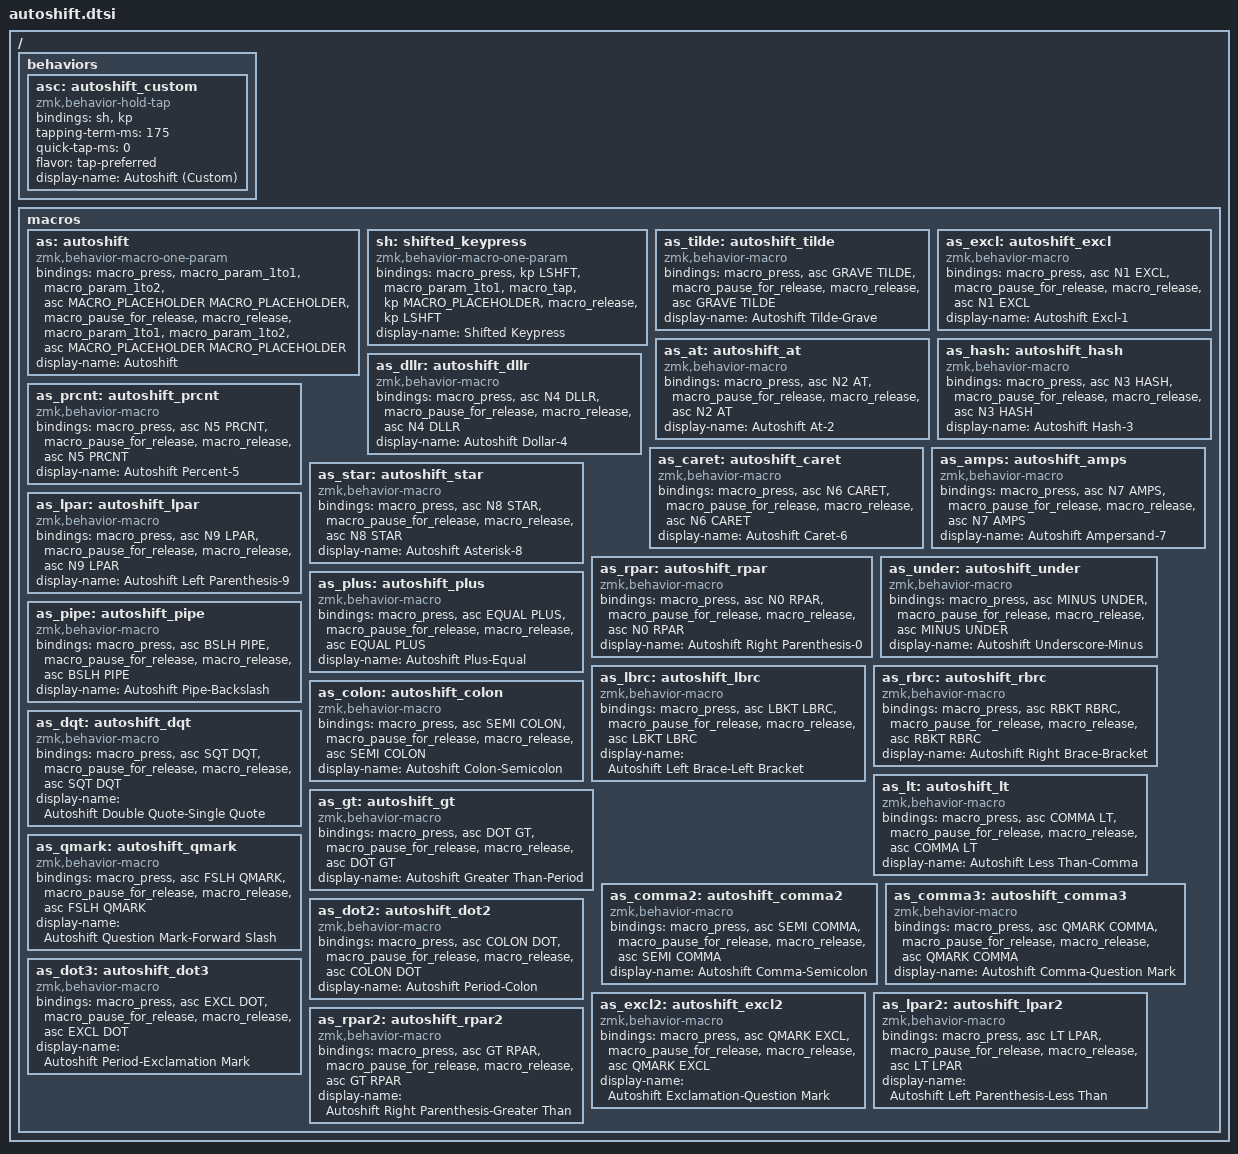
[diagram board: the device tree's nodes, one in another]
#include <dt-bindings/zmk/keys.h>

/ {
    behaviors {
        asc: autoshift_custom {
            compatible = "zmk,behavior-hold-tap";
            #binding-cells = <2>;
            bindings = <&sh>, <&kp>;
            tapping-term-ms = <175>;
            quick-tap-ms = <0>;
            flavor = "tap-preferred";
            display-name = "Autoshift (Custom)";
        };
    };

    macros {
        as: autoshift {
            compatible = "zmk,behavior-macro-one-param";
            #binding-cells = <1>;
            bindings
                = <&macro_press>
                , <&macro_param_1to1>
                , <&macro_param_1to2>
                , <&asc MACRO_PLACEHOLDER MACRO_PLACEHOLDER>
                , <&macro_pause_for_release>
                , <&macro_release>
                , <&macro_param_1to1>
                , <&macro_param_1to2>
                , <&asc MACRO_PLACEHOLDER MACRO_PLACEHOLDER>
                ;
            display-name = "Autoshift";
        };

        sh: shifted_keypress {
            compatible = "zmk,behavior-macro-one-param";
            #binding-cells = <1>;
            bindings
                = <&macro_press &kp LSHFT>
                , <&macro_param_1to1>
                , <&macro_tap &kp MACRO_PLACEHOLDER>
                , <&macro_release &kp LSHFT>
                ;
            display-name = "Shifted Keypress";
        };


        #define AS_TILDE  &asc GRAVE TILDE
        as_tilde:  autoshift_tilde {
            compatible = "zmk,behavior-macro";
            #binding-cells = <0>;
            bindings
                = <&macro_press>
                , <&asc GRAVE TILDE>
                , <&macro_pause_for_release>
                , <&macro_release>
                , <&asc GRAVE TILDE>
                ;
            display-name = "Autoshift Tilde-Grave";
        };

        as_excl: autoshift_excl {
            compatible = "zmk,behavior-macro";
            #binding-cells = <0>;
            bindings
                = <&macro_press>
                , <&asc N1 EXCL>
                , <&macro_pause_for_release>
                , <&macro_release>
                , <&asc N1 EXCL>
                ;
            display-name = "Autoshift Excl-1";
        };

        as_at: autoshift_at {
            compatible = "zmk,behavior-macro";
            #binding-cells = <0>;
            bindings
                = <&macro_press>
                , <&asc N2 AT>
                , <&macro_pause_for_release>
                , <&macro_release>
                , <&asc N2 AT>
                ;
            display-name = "Autoshift At-2";
        };

        as_hash: autoshift_hash {
            compatible = "zmk,behavior-macro";
            #binding-cells = <0>;
            bindings
                = <&macro_press>
                , <&asc N3 HASH>
                , <&macro_pause_for_release>
                , <&macro_release>
                , <&asc N3 HASH>
                ;
            display-name = "Autoshift Hash-3";
        };

        as_dllr: autoshift_dllr {
            compatible = "zmk,behavior-macro";
            #binding-cells = <0>;
            bindings
                = <&macro_press>
                , <&asc N4 DLLR>
                , <&macro_pause_for_release>
                , <&macro_release>
                , <&asc N4 DLLR>
                ;
            display-name = "Autoshift Dollar-4";
        };

        as_prcnt: autoshift_prcnt {
            compatible = "zmk,behavior-macro";
            #binding-cells = <0>;
            bindings
                = <&macro_press>
                , <&asc N5 PRCNT>
                , <&macro_pause_for_release>
                , <&macro_release>
                , <&asc N5 PRCNT>
                ;
            display-name = "Autoshift Percent-5";
        };

        as_caret: autoshift_caret {
            compatible = "zmk,behavior-macro";
            #binding-cells = <0>;
            bindings
                = <&macro_press>
                , <&asc N6 CARET>
                , <&macro_pause_for_release>
                , <&macro_release>
                , <&asc N6 CARET>
                ;
            display-name = "Autoshift Caret-6";
        };

        as_amps: autoshift_amps {
            compatible = "zmk,behavior-macro";
            #binding-cells = <0>;
            bindings
                = <&macro_press>
                , <&asc N7 AMPS>
                , <&macro_pause_for_release>
                , <&macro_release>
                , <&asc N7 AMPS>
                ;
            display-name = "Autoshift Ampersand-7";
        };

        as_star: autoshift_star {
            compatible = "zmk,behavior-macro";
            #binding-cells = <0>;
            bindings
                = <&macro_press>
                , <&asc N8 STAR>
                , <&macro_pause_for_release>
                , <&macro_release>
                , <&asc N8 STAR>
                ;
            display-name = "Autoshift Asterisk-8";
        };

        as_lpar: autoshift_lpar {
            compatible = "zmk,behavior-macro";
            #binding-cells = <0>;
            bindings
                = <&macro_press>
                , <&asc N9 LPAR>
                , <&macro_pause_for_release>
                , <&macro_release>
                , <&asc N9 LPAR>
                ;
            display-name = "Autoshift Left Parenthesis-9";
        };

        as_rpar: autoshift_rpar {
            compatible = "zmk,behavior-macro";
            #binding-cells = <0>;
            bindings
                = <&macro_press>
                , <&asc N0 RPAR>
                , <&macro_pause_for_release>
                , <&macro_release>
                , <&asc N0 RPAR>
                ;
            display-name = "Autoshift Right Parenthesis-0";
        };

        as_under: autoshift_under {
            compatible = "zmk,behavior-macro";
            #binding-cells = <0>;
            bindings
                = <&macro_press>
                , <&asc MINUS UNDER>
                , <&macro_pause_for_release>
                , <&macro_release>
                , <&asc MINUS UNDER>
                ;
            display-name = "Autoshift Underscore-Minus";
        };

        as_plus: autoshift_plus {
            compatible = "zmk,behavior-macro";
            #binding-cells = <0>;
            bindings
                = <&macro_press>
                , <&asc EQUAL PLUS>
                , <&macro_pause_for_release>
                , <&macro_release>
                , <&asc EQUAL PLUS>
                ;
            display-name = "Autoshift Plus-Equal";
        };

        as_pipe: autoshift_pipe {
            compatible = "zmk,behavior-macro";
            #binding-cells = <0>;
            bindings
                = <&macro_press>
                , <&asc BSLH PIPE>
                , <&macro_pause_for_release>
                , <&macro_release>
                , <&asc BSLH PIPE>
                ;
            display-name = "Autoshift Pipe-Backslash";
        };

        as_lbrc: autoshift_lbrc {
            compatible = "zmk,behavior-macro";
            #binding-cells = <0>;
            bindings
                = <&macro_press>
                , <&asc LBKT LBRC>
                , <&macro_pause_for_release>
                , <&macro_release>
                , <&asc LBKT LBRC>
                ;
            display-name = "Autoshift Left Brace-Left Bracket";
        };

        as_rbrc: autoshift_rbrc {
            compatible = "zmk,behavior-macro";
            #binding-cells = <0>;
            bindings
                = <&macro_press>
                , <&asc RBKT RBRC>
                , <&macro_pause_for_release>
                , <&macro_release>
                , <&asc RBKT RBRC>
                ;
            display-name = "Autoshift Right Brace-Bracket";
        };

        as_colon: autoshift_colon {
            compatible = "zmk,behavior-macro";
            #binding-cells = <0>;
            bindings
                = <&macro_press>
                , <&asc SEMI COLON>
                , <&macro_pause_for_release>
                , <&macro_release>
                , <&asc SEMI COLON>
                ;
            display-name = "Autoshift Colon-Semicolon";
        };

        as_dqt: autoshift_dqt {
            compatible = "zmk,behavior-macro";
            #binding-cells = <0>;
            bindings
                = <&macro_press>
                , <&asc SQT DQT>
                , <&macro_pause_for_release>
                , <&macro_release>
                , <&asc SQT DQT>
                ;
            display-name = "Autoshift Double Quote-Single Quote";
        };

        as_lt: autoshift_lt {
            compatible = "zmk,behavior-macro";
            #binding-cells = <0>;
            bindings
                = <&macro_press>
                , <&asc COMMA LT>
                , <&macro_pause_for_release>
                , <&macro_release>
                , <&asc COMMA LT>
                ;
            display-name = "Autoshift Less Than-Comma";
        };

        as_gt: autoshift_gt {
            compatible = "zmk,behavior-macro";
            #binding-cells = <0>;
            bindings
                = <&macro_press>
                , <&asc DOT GT>
                , <&macro_pause_for_release>
                , <&macro_release>
                , <&asc DOT GT>
                ;
            display-name = "Autoshift Greater Than-Period";
        };

        as_qmark: autoshift_qmark {
            compatible = "zmk,behavior-macro";
            #binding-cells = <0>;
            bindings
                = <&macro_press>
                , <&asc FSLH QMARK>
                , <&macro_pause_for_release>
                , <&macro_release>
                , <&asc FSLH QMARK>
                ;
            display-name = "Autoshift Question Mark-Forward Slash";
        };

        // Custom mod-shifts
        as_comma2: autoshift_comma2 {
            compatible = "zmk,behavior-macro";
            #binding-cells = <0>;
            bindings
                = <&macro_press>
                , <&asc SEMI COMMA>
                , <&macro_pause_for_release>
                , <&macro_release>
                , <&asc SEMI COMMA>
                ;
            display-name = "Autoshift Comma-Semicolon";
        };

        as_comma3: autoshift_comma3 {
            compatible = "zmk,behavior-macro";
            #binding-cells = <0>;
            bindings
                = <&macro_press>
                , <&asc QMARK COMMA>
                , <&macro_pause_for_release>
                , <&macro_release>
                , <&asc QMARK COMMA>
                ;
            display-name = "Autoshift Comma-Question Mark";
        };

        as_dot2: autoshift_dot2 {
            compatible = "zmk,behavior-macro";
            #binding-cells = <0>;
            bindings
                = <&macro_press>
                , <&asc COLON DOT>
                , <&macro_pause_for_release>
                , <&macro_release>
                , <&asc COLON DOT>
                ;
            display-name = "Autoshift Period-Colon";
        };

        as_dot3: autoshift_dot3 {
            compatible = "zmk,behavior-macro";
            #binding-cells = <0>;
            bindings
                = <&macro_press>
                , <&asc EXCL DOT>
                , <&macro_pause_for_release>
                , <&macro_release>
                , <&asc EXCL DOT>
                ;
            display-name = "Autoshift Period-Exclamation Mark";
        };

        as_excl2: autoshift_excl2 {
            compatible = "zmk,behavior-macro";
            #binding-cells = <0>;
            bindings
                = <&macro_press>
                , <&asc QMARK EXCL>
                , <&macro_pause_for_release>
                , <&macro_release>
                , <&asc QMARK EXCL>
                ;
            display-name = "Autoshift Exclamation-Question Mark";
        };

        as_lpar2: autoshift_lpar2 {
            compatible = "zmk,behavior-macro";
            #binding-cells = <0>;
            bindings
                = <&macro_press>
                , <&asc LT LPAR>
                , <&macro_pause_for_release>
                , <&macro_release>
                , <&asc LT LPAR>
                ;
            display-name = "Autoshift Left Parenthesis-Less Than";
        };

        as_rpar2: autoshift_rpar2 {
            compatible = "zmk,behavior-macro";
            #binding-cells = <0>;
            bindings
                = <&macro_press>
                , <&asc GT RPAR>
                , <&macro_pause_for_release>
                , <&macro_release>
                , <&asc GT RPAR>
                ;
            display-name = "Autoshift Right Parenthesis-Greater Than";
        };
    };
};
